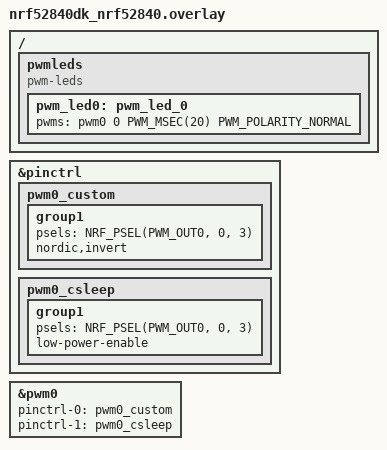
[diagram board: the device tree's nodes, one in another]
// To get started, press Ctrl+Space to bring up the completion menu and view the available nodes.

// You can also use the buttons in the sidebar to perform actions on nodes.
// Actions currently available include:

// * Enabling / disabling the node
// * Adding the bus to a bus
// * Removing the node
// * Connecting ADC channels

// For more help, browse the DeviceTree documentation at https://docs.zephyrproject.org/latest/guides/dts/index.html
// You can also visit the nRF DeviceTree extension documentation at https://nrfconnect.github.io/vscode-nrf-connect/devicetree/nrfdevicetree.html

&pinctrl {
    pwm0_custom: pwm0_custom {
        group1 {
            psels = <NRF_PSEL(PWM_OUT0, 0, 3)>;
            nordic,invert;
        };
    };

    pwm0_csleep: pwm0_csleep {
        group1 {
            psels = <NRF_PSEL(PWM_OUT0, 0, 3)>;
            low-power-enable;
        };
    };
};

&pwm0 {
    status = "okay";
    pinctrl-0 = <&pwm0_custom>;
    pinctrl-1 = <&pwm0_csleep>;
    pinctrl-names = "default", "sleep";
};

/{
    pwmleds {
        compatible = "pwm-leds";
        pwm_led0: pwm_led_0 {
            pwms = <&pwm0 0 PWM_MSEC(20) PWM_POLARITY_NORMAL>;
        };
    };
};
